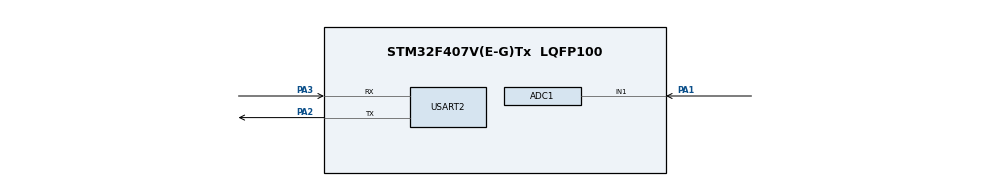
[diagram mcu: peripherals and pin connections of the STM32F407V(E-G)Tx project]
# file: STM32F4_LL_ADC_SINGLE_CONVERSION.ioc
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ADC1.Channel-4\#ChannelRegularConversion=ADC_CHANNEL_1
ADC1.Channel-5\#ChannelRegularConversion=ADC_CHANNEL_TEMPSENSOR
ADC1.Channel-6\#ChannelRegularConversion=ADC_CHANNEL_VREFINT
ADC1.DiscontinuousConvMode=ENABLE
ADC1.NbrOfConversion=3
ADC1.NbrOfConversionFlag=1
ADC1.NbrOfDiscConversion=1
ADC1.Rank-4\#ChannelRegularConversion=1
ADC1.Rank-5\#ChannelRegularConversion=2
ADC1.Rank-6\#ChannelRegularConversion=3
ADC1.SamplingTime-4\#ChannelRegularConversion=ADC_SAMPLETIME_480CYCLES
ADC1.SamplingTime-5\#ChannelRegularConversion=ADC_SAMPLETIME_480CYCLES
ADC1.SamplingTime-6\#ChannelRegularConversion=ADC_SAMPLETIME_480CYCLES
ADC1.ScanConvMode=ENABLE
ADC1.master=1
Mcu.Family=STM32F4
Mcu.Name=STM32F407V(E-G)Tx
Mcu.Package=LQFP100
NVIC.PriorityGroup=NVIC_PRIORITYGROUP_0
PA1.Signal=ADCx_IN1
PA13.Mode=Serial_Wire
PA13.Signal=SYS_JTMS-SWDIO
PA14.Mode=Serial_Wire
PA14.Signal=SYS_JTCK-SWCLK
PA2.Mode=Asynchronous
PA2.Signal=USART2_TX
PA3.Mode=Asynchronous
PA3.Signal=USART2_RX
PH0-OSC_IN.Mode=HSE-External-Oscillator
PH0-OSC_IN.Signal=RCC_OSC_IN
PH1-OSC_OUT.Mode=HSE-External-Oscillator
PH1-OSC_OUT.Signal=RCC_OSC_OUT
ProjectManager.HeapSize=0x200
ProjectManager.StackSize=0x400
ProjectManager.TargetToolchain=STM32CubeIDE
RCC.48MHZClocksFreq_Value=48000000
RCC.AHBFreq_Value=168000000
RCC.APB1CLKDivider=RCC_HCLK_DIV4
RCC.APB1Freq_Value=42000000
RCC.APB1TimFreq_Value=84000000
RCC.APB2CLKDivider=RCC_HCLK_DIV2
RCC.APB2Freq_Value=84000000
RCC.APB2TimFreq_Value=168000000
RCC.CortexFreq_Value=168000000
RCC.HCLKFreq_Value=168000000
RCC.HSE_VALUE=8000000
RCC.HSI_VALUE=16000000
RCC.PLLM=8
RCC.PLLN=336
RCC.PLLQ=7
RCC.PLLSourceVirtual=RCC_PLLSOURCE_HSE
RCC.SYSCLKFreq_VALUE=168000000
RCC.SYSCLKSource=RCC_SYSCLKSOURCE_PLLCLK
RCC.VCOOutputFreq_Value=336000000
SH.ADCx_IN1.0=ADC1_IN1,IN1
USART2.VirtualMode=VM_ASYNC
VP_ADC1_TempSens_Input.Mode=IN-TempSens
VP_ADC1_Vref_Input.Mode=IN-Vrefint
board=STM32F407G-DISC1

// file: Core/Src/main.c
/* USER CODE BEGIN Header */
/**
  ******************************************************************************
  * @file           : main.c
  * @brief          : Main program body
  ******************************************************************************
  * @attention
  *
  * Copyright (c) 2022 STMicroelectronics.
  * All rights reserved.
  *
  * This software is licensed under terms that can be found in the LICENSE file
  * in the root directory of this software component.
  * If no LICENSE file comes with this software, it is provided AS-IS.
  *
  ******************************************************************************
  */
/* USER CODE END Header */
#include "main.h"
#include "adc.h"
#include "usart.h"
#include "gpio.h"

/* USER CODE BEGIN Includes */
#include <stdio.h>
/* USER CODE END Includes */

void SystemClock_Config(void);

/* USER CODE BEGIN 0 */

uint16_t adcValCh1;
uint16_t adcValChTemp;
uint16_t adcValChVrefint;

int __io_putchar (int ch)
{
  while (!LL_USART_IsActiveFlag_TXE(USART2));
  LL_USART_TransmitData8(USART2, (char)ch);
  return ch;
}

/* USER CODE END 0 */

int main(void)
{

  /* MCU Configuration--------------------------------------------------------*/

  /* Reset of all peripherals, Initializes the Flash interface and the Systick. */
  LL_APB2_GRP1_EnableClock(LL_APB2_GRP1_PERIPH_SYSCFG);
  LL_APB1_GRP1_EnableClock(LL_APB1_GRP1_PERIPH_PWR);

  /* System interrupt init*/
  NVIC_SetPriorityGrouping(NVIC_PRIORITYGROUP_0);

  /* Configure the system clock */
  SystemClock_Config();

  /* Initialize all configured peripherals */
  MX_GPIO_Init();
  MX_ADC1_Init();
  MX_USART2_UART_Init();
  /* USER CODE BEGIN 2 */

  // enable ADC
  LL_ADC_Enable(ADC1);

  /* USER CODE END 2 */

  /* Infinite loop */
  /* USER CODE BEGIN WHILE */
  while (1)
  {
    // start conversion
    LL_ADC_REG_StartConversionSWStart(ADC1);

    // wait end of conversion flag
    while(!LL_ADC_IsActiveFlag_EOCS(ADC1));

    // clear flag
    LL_ADC_ClearFlag_EOCS(ADC1);

    // read channel1 data
    adcValCh1 = LL_ADC_REG_ReadConversionData12(ADC1);

    // start conversion
    LL_ADC_REG_StartConversionSWStart(ADC1);

    // wait end of conversion flag
    while(!LL_ADC_IsActiveFlag_EOCS(ADC1));

    // clear flag
    LL_ADC_ClearFlag_EOCS(ADC1);

    // read temperature channel data
    adcValChTemp = LL_ADC_REG_ReadConversionData12(ADC1);
    float temp = (float)adcValChTemp * 3.3f / 4096.0f;
    temp = (temp - 0.76) / 0.0025 + 25;

    // start conversion
    LL_ADC_REG_StartConversionSWStart(ADC1);

    // wait end of conversion flag
    while(!LL_ADC_IsActiveFlag_EOCS(ADC1));

    // clear flag
    LL_ADC_ClearFlag_EOCS(ADC1);

    // read Vrefint channel data
    adcValChVrefint = LL_ADC_REG_ReadConversionData12(ADC1);

    // Vdd = 3.3V * Vrefint_cal / Vrefint
    // (*VREFINT_CAL_ADDR) is calibrated value when Vdda is 3.3V
    float Vdd = 3.3f * (*VREFINT_CAL_ADDR) / adcValChVrefint;

    // print adc results
    printf("ADC CH1: %d, TEMP: %2.1f, Vdd: %1.2f\r\n", adcValCh1, temp, Vdd);

    LL_mDelay(1000);

    /* USER CODE END WHILE */

  }
}

void SystemClock_Config(void)
{
  LL_FLASH_SetLatency(LL_FLASH_LATENCY_5);
  while(LL_FLASH_GetLatency()!= LL_FLASH_LATENCY_5)
  {
  }
  LL_PWR_SetRegulVoltageScaling(LL_PWR_REGU_VOLTAGE_SCALE1);
  LL_RCC_HSE_Enable();

   /* Wait till HSE is ready */
  while(LL_RCC_HSE_IsReady() != 1)
  {

  }
  LL_RCC_PLL_ConfigDomain_SYS(LL_RCC_PLLSOURCE_HSE, LL_RCC_PLLM_DIV_8, 336, LL_RCC_PLLP_DIV_2);
  LL_RCC_PLL_Enable();

   /* Wait till PLL is ready */
  while(LL_RCC_PLL_IsReady() != 1)
  {

  }
  LL_RCC_SetAHBPrescaler(LL_RCC_SYSCLK_DIV_1);
  LL_RCC_SetAPB1Prescaler(LL_RCC_APB1_DIV_4);
  LL_RCC_SetAPB2Prescaler(LL_RCC_APB2_DIV_2);
  LL_RCC_SetSysClkSource(LL_RCC_SYS_CLKSOURCE_PLL);

   /* Wait till System clock is ready */
  while(LL_RCC_GetSysClkSource() != LL_RCC_SYS_CLKSOURCE_STATUS_PLL)
  {

  }
  LL_Init1msTick(168000000);
  LL_SetSystemCoreClock(168000000);
}

void Error_Handler(void)
{
  __disable_irq();
  while (1)
  {
  }
}
